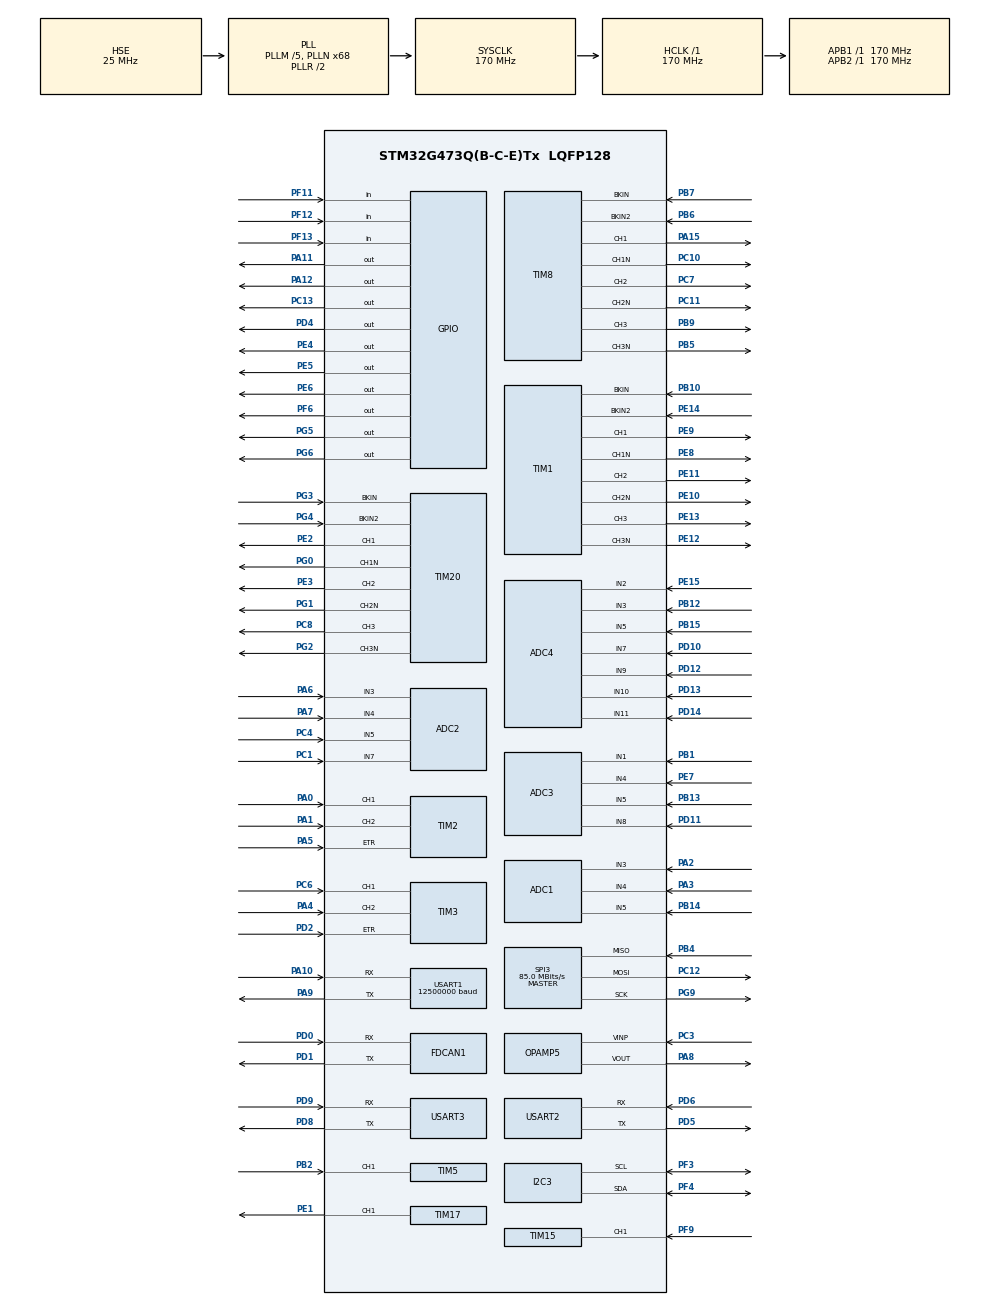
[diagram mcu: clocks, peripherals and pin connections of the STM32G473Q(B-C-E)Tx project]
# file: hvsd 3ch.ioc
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ADC1.Channel-0\#ChannelRegularConversion=ADC_CHANNEL_3
ADC1.ClockPrescaler=ADC_CLOCK_SYNC_PCLK_DIV4
ADC1.NbrOfConversionFlag=1
ADC1.OffsetNumber-0\#ChannelRegularConversion=ADC_OFFSET_NONE
ADC1.Rank-0\#ChannelRegularConversion=1
ADC1.SamplingTime-0\#ChannelRegularConversion=ADC_SAMPLETIME_2CYCLES_5
ADC1.master=1
ADC2.Channel-1\#ChannelRegularConversion=ADC_CHANNEL_3
ADC2.NbrOfConversionFlag=1
ADC2.OffsetNumber-1\#ChannelRegularConversion=ADC_OFFSET_NONE
ADC2.Rank-1\#ChannelRegularConversion=1
ADC2.SamplingTime-1\#ChannelRegularConversion=ADC_SAMPLETIME_2CYCLES_5
ADC3.Channel-1\#ChannelRegularConversion=ADC_CHANNEL_1
ADC3.NbrOfConversionFlag=1
ADC3.OffsetNumber-1\#ChannelRegularConversion=ADC_OFFSET_NONE
ADC3.Rank-1\#ChannelRegularConversion=1
ADC3.SamplingTime-1\#ChannelRegularConversion=ADC_SAMPLETIME_2CYCLES_5
ADC3.master=1
ADC4.Channel-0\#ChannelRegularConversion=ADC_CHANNEL_3
ADC4.NbrOfConversionFlag=1
ADC4.OffsetNumber-0\#ChannelRegularConversion=ADC_OFFSET_NONE
ADC4.Rank-0\#ChannelRegularConversion=1
ADC4.SamplingTime-0\#ChannelRegularConversion=ADC_SAMPLETIME_2CYCLES_5
FDCAN1.CalculateBaudRateNominal=3541666
FDCAN1.CalculateTimeBitNominal=282
FDCAN1.CalculateTimeQuantumNominal=94.11764705882354
I2C3.Timing=0x40B285C2
Mcu.Family=STM32G4
Mcu.Name=STM32G473Q(B-C-E)Tx
Mcu.Package=LQFP128
NVIC.PriorityGroup=NVIC_PRIORITYGROUP_4
OPAMP5.PowerMode=OPAMP_POWERMODE_NORMALSPEED
PA0.Signal=S_TIM2_CH1
PA1.Signal=S_TIM2_CH2
PA10.Mode=Asynchronous
PA10.Signal=USART1_RX
PA11.Signal=GPIO_Output
PA12.Signal=GPIO_Output
PA13.Signal=SYS_JTMS-SWDIO
PA14.Signal=SYS_JTCK-SWCLK
PA15.Signal=S_TIM8_CH1
PA2.Mode=IN3-Single-Ended
PA2.Signal=ADC1_IN3
PA3.Mode=IN4-Single-Ended
PA3.Signal=ADC1_IN4
PA4.Signal=S_TIM3_CH2
PA5.Signal=S_TIM2_ETR
PA6.Mode=IN3-Single-Ended
PA6.Signal=ADC2_IN3
PA7.Mode=IN4-Single-Ended
PA7.Signal=ADC2_IN4
PA8.Mode=Follower
PA8.Signal=OPAMP5_VOUT
PA9.Mode=Asynchronous
PA9.Signal=USART1_TX
PB0.Signal=OPAMP2_VINP
PB1.Mode=IN1-Single-Ended
PB1.Signal=ADC3_IN1
PB10.Mode=Activate-Break-Input
PB10.Signal=TIM1_BKIN
PB12.Mode=IN3-Single-Ended
PB12.Signal=ADC4_IN3
PB13.Mode=IN5-Single-Ended
PB13.Signal=ADC3_IN5
PB14.Mode=IN5-Single-Ended
PB14.Signal=ADC1_IN5
PB15.Mode=IN5-Single-Ended
PB15.Signal=ADC4_IN5
PB2.Signal=S_TIM5_CH1
PB3.Signal=SYS_JTDO-SWO
PB4.Mode=Full_Duplex_Master
PB4.Signal=SPI3_MISO
PB5.Mode=PWM Generation3 CH3 CH3N
PB5.Signal=TIM8_CH3N
PB6.Mode=Activate-Break-Input-2
PB6.Signal=TIM8_BKIN2
PB7.Mode=Activate-Break-Input
PB7.Signal=TIM8_BKIN
PB9.Signal=S_TIM8_CH3
PC1.Mode=IN7-Single-Ended
PC1.Signal=ADC2_IN7
PC10.Mode=PWM Generation1 CH1 CH1N
PC10.Signal=TIM8_CH1N
PC11.Mode=PWM Generation2 CH2 CH2N
PC11.Signal=TIM8_CH2N
PC12.Mode=Full_Duplex_Master
PC12.Signal=SPI3_MOSI
PC13.Signal=GPIO_Output
PC3.Mode=Follower
PC3.Signal=OPAMP5_VINP
PC4.Mode=IN5-Single-Ended
PC4.Signal=ADC2_IN5
PC6.Signal=S_TIM3_CH1
PC7.Signal=S_TIM8_CH2
PC8.Signal=S_TIM20_CH3
PD0.Mode=FDCAN_Activate
PD0.Signal=FDCAN1_RX
PD1.Mode=FDCAN_Activate
PD1.Signal=FDCAN1_TX
PD10.Mode=IN7-Single-Ended
PD10.Signal=ADC4_IN7
PD11.Mode=IN8-Single-Ended
PD11.Signal=ADC3_IN8
PD12.Mode=IN9-Single-Ended
PD12.Signal=ADC4_IN9
PD13.Mode=IN10-Single-Ended
PD13.Signal=ADC4_IN10
PD14.Mode=IN11-Single-Ended
PD14.Signal=ADC4_IN11
PD2.Signal=S_TIM3_ETR
PD4.Signal=GPIO_Output
PD5.Mode=Asynchronous
PD5.Signal=USART2_TX
PD6.Mode=Asynchronous
PD6.Signal=USART2_RX
PD8.Mode=Asynchronous
PD8.Signal=USART3_TX
PD9.Mode=Asynchronous
PD9.Signal=USART3_RX
PE0.Signal=S_TIM4_ETR
PE1.Signal=S_TIM17_CH1
PE10.Mode=PWM Generation2 CH2 CH2N
PE10.Signal=TIM1_CH2N
PE11.Signal=S_TIM1_CH2
PE12.Mode=PWM Generation3 CH3 CH3N
PE12.Signal=TIM1_CH3N
PE13.Signal=S_TIM1_CH3
PE14.Mode=Activate-Break-Input-2
PE14.Signal=TIM1_BKIN2
PE15.Mode=IN2-Single-Ended
PE15.Signal=ADC4_IN2
PE2.Signal=S_TIM20_CH1
PE3.Signal=S_TIM20_CH2
PE4.Signal=GPIO_Output
PE5.Signal=GPIO_Output
PE6.Signal=GPIO_Output
PE7.Mode=IN4-Single-Ended
PE7.Signal=ADC3_IN4
PE8.Mode=PWM Generation1 CH1 CH1N
PE8.Signal=TIM1_CH1N
PE9.Signal=S_TIM1_CH1
PF0-OSC_IN.Mode=HSE-External-Clock-Source
PF0-OSC_IN.Signal=RCC_OSC_IN
PF11.Signal=GPIO_Input
PF12.Signal=GPIO_Input
PF13.Signal=GPIO_Input
PF3.Mode=I2C
PF3.Signal=I2C3_SCL
PF4.Mode=I2C
PF4.Signal=I2C3_SDA
PF6.Signal=GPIO_Output
PF9.Signal=S_TIM15_CH1
PG0.Mode=PWM Generation1 CH1 CH1N
PG0.Signal=TIM20_CH1N
PG1.Mode=PWM Generation2 CH2 CH2N
PG1.Signal=TIM20_CH2N
PG2.Mode=PWM Generation3 CH3 CH3N
PG2.Signal=TIM20_CH3N
PG3.Mode=Activate-Break-Input
PG3.Signal=TIM20_BKIN
PG4.Mode=Activate-Break-Input-2
PG4.Signal=TIM20_BKIN2
PG5.Signal=GPIO_Output
PG6.Signal=GPIO_Output
PG9.Mode=Full_Duplex_Master
PG9.Signal=SPI3_SCK
ProjectManager.HeapSize=0x200
ProjectManager.StackSize=0x400
ProjectManager.TargetToolchain=STM32CubeIDE
RCC.ADC12Freq_Value=170000000
RCC.ADC345Freq_Value=170000000
RCC.AHBFreq_Value=170000000
RCC.APB1Freq_Value=170000000
RCC.APB1TimFreq_Value=170000000
RCC.APB2Freq_Value=170000000
RCC.APB2TimFreq_Value=170000000
RCC.CK48CLockSelection=RCC_USBCLKSOURCE_HSI48
RCC.CortexFreq_Value=170000000
RCC.EXTERNAL_CLOCK_VALUE=12288000
RCC.HCLKFreq_Value=170000000
RCC.HSE_VALUE=25000000
RCC.HSI48_VALUE=48000000
RCC.HSI_VALUE=16000000
RCC.LSE_VALUE=32768
RCC.PLLM=RCC_PLLM_DIV4
RCC.PLLN=85
RCC.PLLP=RCC_PLLP_DIV7
RCC.SYSCLKFreq_VALUE=170000000
RCC.SYSCLKSource=RCC_SYSCLKSOURCE_PLLCLK
RCC.USART2CLockSelection=RCC_USART2CLKSOURCE_SYSCLK
RCC.USART3CLockSelection=RCC_USART3CLKSOURCE_SYSCLK
RCC.USBFreq_Value=48000000
RCC.VCOOutputFreq_Value=340000000
SH.S_TIM15_CH1.0=TIM15_CH1,TriggerSource_TI1FP1
SH.S_TIM17_CH1.0=TIM17_CH1,PWM Generation1 CH1
SH.S_TIM1_CH1.0=TIM1_CH1,PWM Generation1 CH1 CH1N
SH.S_TIM1_CH2.0=TIM1_CH2,PWM Generation2 CH2 CH2N
SH.S_TIM1_CH3.0=TIM1_CH3,PWM Generation3 CH3 CH3N
SH.S_TIM20_CH1.0=TIM20_CH1,PWM Generation1 CH1 CH1N
SH.S_TIM20_CH2.0=TIM20_CH2,PWM Generation2 CH2 CH2N
SH.S_TIM20_CH3.0=TIM20_CH3,PWM Generation3 CH3 CH3N
SH.S_TIM2_CH1.0=TIM2_CH1,Encoder_Interface_w_index
SH.S_TIM2_CH2.0=TIM2_CH2,Encoder_Interface_w_index
SH.S_TIM2_ETR.0=TIM2_ETR,Encoder_Interface_w_index
SH.S_TIM3_CH1.0=TIM3_CH1,Encoder_Interface_w_index
SH.S_TIM3_CH2.0=TIM3_CH2,Encoder_Interface_w_index
SH.S_TIM3_ETR.0=TIM3_ETR,Encoder_Interface_w_index
SH.S_TIM4_ETR.0=TIM4_ETR
SH.S_TIM5_CH1.0=TIM5_CH1,Input_Capture1_from_TI1
SH.S_TIM8_CH1.0=TIM8_CH1,PWM Generation1 CH1 CH1N
SH.S_TIM8_CH2.0=TIM8_CH2,PWM Generation2 CH2 CH2N
SH.S_TIM8_CH3.0=TIM8_CH3,PWM Generation3 CH3 CH3N
SPI3.BaudRatePrescaler=SPI_BAUDRATEPRESCALER_2
SPI3.CalculateBaudRate=85.0 MBits/s
SPI3.Direction=SPI_DIRECTION_2LINES
SPI3.Mode=SPI_MODE_MASTER
SPI3.VirtualType=VM_MASTER
TIM1.Channel-PWM\ Generation1\ CH1\ CH1N=TIM_CHANNEL_1
TIM1.Channel-PWM\ Generation2\ CH2\ CH2N=TIM_CHANNEL_2
TIM1.Channel-PWM\ Generation3\ CH3\ CH3N=TIM_CHANNEL_3
TIM15.Slave_TriggerFilter=15
TIM17.AutoReloadPreload=TIM_AUTORELOAD_PRELOAD_ENABLE
TIM17.Channel=TIM_CHANNEL_1
TIM17.PeriodNoDither=1000
TIM17.Prescaler=3
TIM17.PulseNoDither_1=500
TIM20.Channel-PWM\ Generation1\ CH1\ CH1N=TIM_CHANNEL_1
TIM20.Channel-PWM\ Generation2\ CH2\ CH2N=TIM_CHANNEL_2
TIM20.Channel-PWM\ Generation3\ CH3\ CH3N=TIM_CHANNEL_3
TIM5.Channel-Input_Capture1_from_TI1=TIM_CHANNEL_1
TIM8.Channel-PWM\ Generation1\ CH1\ CH1N=TIM_CHANNEL_1
TIM8.Channel-PWM\ Generation2\ CH2\ CH2N=TIM_CHANNEL_2
TIM8.Channel-PWM\ Generation3\ CH3\ CH3N=TIM_CHANNEL_3
USART1.BaudRate=12500000
USART1.OverSampling=UART_OVERSAMPLING_8
USART1.SwapParam=ADVFEATURE_SWAP_DISABLE
USART1.VirtualMode-Asynchronous=VM_ASYNC
USART2.VirtualMode-Asynchronous=VM_ASYNC
USART3.VirtualMode-Asynchronous=VM_ASYNC
VP_CORDIC_VS_CORDIC.Mode=CORDIC_Activate
VP_CRC_VS_CRC.Mode=CRC_Activate
VP_FMAC_VS_FMAC.Mode=FMAC_Activate
VP_SYS_VS_DBSignals.Mode=DisableDeadBatterySignals
VP_TIM15_VS_ControllerModeClock.Mode=Clock Mode
VP_TIM17_VS_ClockSourceINT.Mode=Enable_Timer
VP_TIM1_VS_ClockSourceINT.Mode=Internal
VP_TIM20_VS_ClockSourceINT.Mode=Internal
VP_TIM8_VS_ClockSourceINT.Mode=Internal
board=custom

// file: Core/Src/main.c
/* USER CODE BEGIN Header */
/**
  ******************************************************************************
  * @file           : main.c
  * @brief          : Main program body
  ******************************************************************************
  * @attention
  *
  * Copyright (c) 2025 STMicroelectronics.
  * All rights reserved.
  *
  * This software is licensed under terms that can be found in the LICENSE file
  * in the root directory of this software component.
  * If no LICENSE file comes with this software, it is provided AS-IS.
  *
  ******************************************************************************
  */
/* USER CODE END Header */
#include "main.h"

ADC_HandleTypeDef hadc1;
ADC_HandleTypeDef hadc2;
ADC_HandleTypeDef hadc3;
ADC_HandleTypeDef hadc4;

CORDIC_HandleTypeDef hcordic;

CRC_HandleTypeDef hcrc;

FDCAN_HandleTypeDef hfdcan1;

FMAC_HandleTypeDef hfmac;

I2C_HandleTypeDef hi2c3;

OPAMP_HandleTypeDef hopamp5;

SPI_HandleTypeDef hspi3;

TIM_HandleTypeDef htim1;
TIM_HandleTypeDef htim2;
TIM_HandleTypeDef htim3;
TIM_HandleTypeDef htim5;
TIM_HandleTypeDef htim8;
TIM_HandleTypeDef htim15;
TIM_HandleTypeDef htim17;
TIM_HandleTypeDef htim20;

UART_HandleTypeDef huart1;
UART_HandleTypeDef huart2;
UART_HandleTypeDef huart3;

void SystemClock_Config(void);
static void MX_GPIO_Init(void);
static void MX_TIM1_Init(void);
static void MX_TIM8_Init(void);
static void MX_TIM20_Init(void);
static void MX_ADC1_Init(void);
static void MX_ADC2_Init(void);
static void MX_ADC3_Init(void);
static void MX_CORDIC_Init(void);
static void MX_CRC_Init(void);
static void MX_FMAC_Init(void);
static void MX_TIM2_Init(void);
static void MX_TIM3_Init(void);
static void MX_USART1_UART_Init(void);
static void MX_OPAMP5_Init(void);
static void MX_FDCAN1_Init(void);
static void MX_I2C3_Init(void);
static void MX_SPI3_Init(void);
static void MX_TIM5_Init(void);
static void MX_TIM15_Init(void);
static void MX_TIM17_Init(void);
static void MX_USART2_UART_Init(void);
static void MX_USART3_UART_Init(void);
static void MX_ADC4_Init(void);

int main(void)
{

  /* MCU Configuration--------------------------------------------------------*/

  /* Reset of all peripherals, Initializes the Flash interface and the Systick. */
  HAL_Init();

  /* Configure the system clock */
  SystemClock_Config();

  /* Initialize all configured peripherals */
  MX_GPIO_Init();
  MX_TIM1_Init();
  MX_TIM8_Init();
  MX_TIM20_Init();
  MX_ADC1_Init();
  MX_ADC2_Init();
  MX_ADC3_Init();
  MX_CORDIC_Init();
  MX_CRC_Init();
  MX_FMAC_Init();
  MX_TIM2_Init();
  MX_TIM3_Init();
  MX_USART1_UART_Init();
  MX_OPAMP5_Init();
  MX_FDCAN1_Init();
  MX_I2C3_Init();
  MX_SPI3_Init();
  MX_TIM5_Init();
  MX_TIM15_Init();
  MX_TIM17_Init();
  MX_USART2_UART_Init();
  MX_USART3_UART_Init();
  MX_ADC4_Init();
  /* USER CODE BEGIN 2 */

  HAL_TIM_PWM_Start(&htim17, TIM_CHANNEL_1);

  /* USER CODE END 2 */

  /* Infinite loop */
  /* USER CODE BEGIN WHILE */
  while (1)
  {

	for(uint16_t val = 0; val < 999; val++){
		TIM17->CCR1 = val;
		HAL_Delay(20);
	}

	for(uint16_t val = 999; val > 0; val--){
		TIM17->CCR1 = val;
		HAL_Delay(20);
	}

//	// port 1 led 0
//	HAL_GPIO_WritePin(GPIOE, GPIO_PIN_6, GPIO_PIN_SET);
//	HAL_Delay(500);
//
//	HAL_GPIO_WritePin(GPIOE, GPIO_PIN_6, GPIO_PIN_RESET);
//	HAL_Delay(500);
//
//	// port 1 led 1
//	HAL_GPIO_WritePin(GPIOE, GPIO_PIN_5, GPIO_PIN_SET);
//	HAL_Delay(500);
//
//	HAL_GPIO_WritePin(GPIOE, GPIO_PIN_5, GPIO_PIN_RESET);
//	HAL_Delay(500);
//
//	// port 2 led 0
//	HAL_GPIO_WritePin(GPIOC, GPIO_PIN_13, GPIO_PIN_SET);
//	HAL_Delay(500);
//
//	HAL_GPIO_WritePin(GPIOC, GPIO_PIN_13, GPIO_PIN_RESET);
//	HAL_Delay(500);
//
//	// port 2 led 1
//	HAL_GPIO_WritePin(GPIOE, GPIO_PIN_4, GPIO_PIN_SET);
//	HAL_Delay(500);
//
//	HAL_GPIO_WritePin(GPIOE, GPIO_PIN_4, GPIO_PIN_RESET);
//	HAL_Delay(500);
//
//	// port 1 led 1
//	HAL_GPIO_WritePin(GPIOA, GPIO_PIN_11, GPIO_PIN_SET);
//	HAL_Delay(500);
//
//	HAL_GPIO_WritePin(GPIOA, GPIO_PIN_11, GPIO_PIN_RESET);
//	HAL_Delay(500);
//
//	// port 1 led 1
//	HAL_GPIO_WritePin(GPIOA, GPIO_PIN_12, GPIO_PIN_SET);
//	HAL_Delay(500);
//
//	HAL_GPIO_WritePin(GPIOA, GPIO_PIN_12, GPIO_PIN_RESET);
//	HAL_Delay(500);

    /* USER CODE END WHILE */

  }
}

void SystemClock_Config(void)
{
  RCC_OscInitTypeDef RCC_OscInitStruct = {0};
  RCC_ClkInitTypeDef RCC_ClkInitStruct = {0};

  /** Configure the main internal regulator output voltage
  */
  HAL_PWREx_ControlVoltageScaling(PWR_REGULATOR_VOLTAGE_SCALE1_BOOST);

  /** Initializes the RCC Oscillators according to the specified parameters
  * in the RCC_OscInitTypeDef structure.
  */
  RCC_OscInitStruct.OscillatorType = RCC_OSCILLATORTYPE_HSE;
  RCC_OscInitStruct.HSEState = RCC_HSE_BYPASS;
  RCC_OscInitStruct.PLL.PLLState = RCC_PLL_ON;
  RCC_OscInitStruct.PLL.PLLSource = RCC_PLLSOURCE_HSE;
  RCC_OscInitStruct.PLL.PLLM = RCC_PLLM_DIV5;
  RCC_OscInitStruct.PLL.PLLN = 68;
  RCC_OscInitStruct.PLL.PLLP = RCC_PLLP_DIV2;
  RCC_OscInitStruct.PLL.PLLQ = RCC_PLLQ_DIV2;
  RCC_OscInitStruct.PLL.PLLR = RCC_PLLR_DIV2;
  if (HAL_RCC_OscConfig(&RCC_OscInitStruct) != HAL_OK)
  {
    Error_Handler();
  }

  /** Initializes the CPU, AHB and APB buses clocks
  */
  RCC_ClkInitStruct.ClockType = RCC_CLOCKTYPE_HCLK|RCC_CLOCKTYPE_SYSCLK
                              |RCC_CLOCKTYPE_PCLK1|RCC_CLOCKTYPE_PCLK2;
  RCC_ClkInitStruct.SYSCLKSource = RCC_SYSCLKSOURCE_PLLCLK;
  RCC_ClkInitStruct.AHBCLKDivider = RCC_SYSCLK_DIV1;
  RCC_ClkInitStruct.APB1CLKDivider = RCC_HCLK_DIV1;
  RCC_ClkInitStruct.APB2CLKDivider = RCC_HCLK_DIV1;

  if (HAL_RCC_ClockConfig(&RCC_ClkInitStruct, FLASH_LATENCY_4) != HAL_OK)
  {
    Error_Handler();
  }
}

static void MX_ADC1_Init(void)
{

  ADC_MultiModeTypeDef multimode = {0};
  ADC_ChannelConfTypeDef sConfig = {0};

  /** Common config
  */
  hadc1.Instance = ADC1;
  hadc1.Init.ClockPrescaler = ADC_CLOCK_SYNC_PCLK_DIV4;
  hadc1.Init.Resolution = ADC_RESOLUTION_12B;
  hadc1.Init.DataAlign = ADC_DATAALIGN_RIGHT;
  hadc1.Init.GainCompensation = 0;
  hadc1.Init.ScanConvMode = ADC_SCAN_DISABLE;
  hadc1.Init.EOCSelection = ADC_EOC_SINGLE_CONV;
  hadc1.Init.LowPowerAutoWait = DISABLE;
  hadc1.Init.ContinuousConvMode = DISABLE;
  hadc1.Init.NbrOfConversion = 1;
  hadc1.Init.DiscontinuousConvMode = DISABLE;
  hadc1.Init.ExternalTrigConv = ADC_SOFTWARE_START;
  hadc1.Init.ExternalTrigConvEdge = ADC_EXTERNALTRIGCONVEDGE_NONE;
  hadc1.Init.DMAContinuousRequests = DISABLE;
  hadc1.Init.Overrun = ADC_OVR_DATA_PRESERVED;
  hadc1.Init.OversamplingMode = DISABLE;
  if (HAL_ADC_Init(&hadc1) != HAL_OK)
  {
    Error_Handler();
  }

  /** Configure the ADC multi-mode
  */
  multimode.Mode = ADC_MODE_INDEPENDENT;
  if (HAL_ADCEx_MultiModeConfigChannel(&hadc1, &multimode) != HAL_OK)
  {
    Error_Handler();
  }

  /** Configure Regular Channel
  */
  sConfig.Channel = ADC_CHANNEL_3;
  sConfig.Rank = ADC_REGULAR_RANK_1;
  sConfig.SamplingTime = ADC_SAMPLETIME_2CYCLES_5;
  sConfig.SingleDiff = ADC_SINGLE_ENDED;
  sConfig.OffsetNumber = ADC_OFFSET_NONE;
  sConfig.Offset = 0;
  if (HAL_ADC_ConfigChannel(&hadc1, &sConfig) != HAL_OK)
  {
    Error_Handler();
  }

}

static void MX_ADC2_Init(void)
{

  ADC_ChannelConfTypeDef sConfig = {0};

  /** Common config
  */
  hadc2.Instance = ADC2;
  hadc2.Init.ClockPrescaler = ADC_CLOCK_SYNC_PCLK_DIV4;
  hadc2.Init.Resolution = ADC_RESOLUTION_12B;
  hadc2.Init.DataAlign = ADC_DATAALIGN_RIGHT;
  hadc2.Init.GainCompensation = 0;
  hadc2.Init.ScanConvMode = ADC_SCAN_DISABLE;
  hadc2.Init.EOCSelection = ADC_EOC_SINGLE_CONV;
  hadc2.Init.LowPowerAutoWait = DISABLE;
  hadc2.Init.ContinuousConvMode = DISABLE;
  hadc2.Init.NbrOfConversion = 1;
  hadc2.Init.DiscontinuousConvMode = DISABLE;
  hadc2.Init.ExternalTrigConv = ADC_SOFTWARE_START;
  hadc2.Init.ExternalTrigConvEdge = ADC_EXTERNALTRIGCONVEDGE_NONE;
  hadc2.Init.DMAContinuousRequests = DISABLE;
  hadc2.Init.Overrun = ADC_OVR_DATA_PRESERVED;
  hadc2.Init.OversamplingMode = DISABLE;
  if (HAL_ADC_Init(&hadc2) != HAL_OK)
  {
    Error_Handler();
  }

  /** Configure Regular Channel
  */
  sConfig.Channel = ADC_CHANNEL_3;
  sConfig.Rank = ADC_REGULAR_RANK_1;
  sConfig.SamplingTime = ADC_SAMPLETIME_2CYCLES_5;
  sConfig.SingleDiff = ADC_SINGLE_ENDED;
  sConfig.OffsetNumber = ADC_OFFSET_NONE;
  sConfig.Offset = 0;
  if (HAL_ADC_ConfigChannel(&hadc2, &sConfig) != HAL_OK)
  {
    Error_Handler();
  }

}

static void MX_ADC3_Init(void)
{

  ADC_MultiModeTypeDef multimode = {0};
  ADC_ChannelConfTypeDef sConfig = {0};

  /** Common config
  */
  hadc3.Instance = ADC3;
  hadc3.Init.ClockPrescaler = ADC_CLOCK_SYNC_PCLK_DIV4;
  hadc3.Init.Resolution = ADC_RESOLUTION_12B;
  hadc3.Init.DataAlign = ADC_DATAALIGN_RIGHT;
  hadc3.Init.GainCompensation = 0;
  hadc3.Init.ScanConvMode = ADC_SCAN_DISABLE;
  hadc3.Init.EOCSelection = ADC_EOC_SINGLE_CONV;
  hadc3.Init.LowPowerAutoWait = DISABLE;
  hadc3.Init.ContinuousConvMode = DISABLE;
  hadc3.Init.NbrOfConversion = 1;
  hadc3.Init.DiscontinuousConvMode = DISABLE;
  hadc3.Init.ExternalTrigConv = ADC_SOFTWARE_START;
  hadc3.Init.ExternalTrigConvEdge = ADC_EXTERNALTRIGCONVEDGE_NONE;
  hadc3.Init.DMAContinuousRequests = DISABLE;
  hadc3.Init.Overrun = ADC_OVR_DATA_PRESERVED;
  hadc3.Init.OversamplingMode = DISABLE;
  if (HAL_ADC_Init(&hadc3) != HAL_OK)
  {
    Error_Handler();
  }

  /** Configure the ADC multi-mode
  */
  multimode.Mode = ADC_MODE_INDEPENDENT;
  if (HAL_ADCEx_MultiModeConfigChannel(&hadc3, &multimode) != HAL_OK)
  {
    Error_Handler();
  }

  /** Configure Regular Channel
  */
  sConfig.Channel = ADC_CHANNEL_1;
  sConfig.Rank = ADC_REGULAR_RANK_1;
  sConfig.SamplingTime = ADC_SAMPLETIME_2CYCLES_5;
  sConfig.SingleDiff = ADC_SINGLE_ENDED;
  sConfig.OffsetNumber = ADC_OFFSET_NONE;
  sConfig.Offset = 0;
  if (HAL_ADC_ConfigChannel(&hadc3, &sConfig) != HAL_OK)
  {
    Error_Handler();
  }

}

static void MX_ADC4_Init(void)
{

  ADC_ChannelConfTypeDef sConfig = {0};

  /** Common config
  */
  hadc4.Instance = ADC4;
  hadc4.Init.ClockPrescaler = ADC_CLOCK_SYNC_PCLK_DIV4;
  hadc4.Init.Resolution = ADC_RESOLUTION_12B;
  hadc4.Init.DataAlign = ADC_DATAALIGN_RIGHT;
  hadc4.Init.GainCompensation = 0;
  hadc4.Init.ScanConvMode = ADC_SCAN_DISABLE;
  hadc4.Init.EOCSelection = ADC_EOC_SINGLE_CONV;
  hadc4.Init.LowPowerAutoWait = DISABLE;
  hadc4.Init.ContinuousConvMode = DISABLE;
  hadc4.Init.NbrOfConversion = 1;
  hadc4.Init.DiscontinuousConvMode = DISABLE;
  hadc4.Init.ExternalTrigConv = ADC_SOFTWARE_START;
  hadc4.Init.ExternalTrigConvEdge = ADC_EXTERNALTRIGCONVEDGE_NONE;
  hadc4.Init.DMAContinuousRequests = DISABLE;
  hadc4.Init.Overrun = ADC_OVR_DATA_PRESERVED;
  hadc4.Init.OversamplingMode = DISABLE;
  if (HAL_ADC_Init(&hadc4) != HAL_OK)
  {
    Error_Handler();
  }

  /** Configure Regular Channel
  */
  sConfig.Channel = ADC_CHANNEL_3;
  sConfig.Rank = ADC_REGULAR_RANK_1;
  sConfig.SamplingTime = ADC_SAMPLETIME_2CYCLES_5;
  sConfig.SingleDiff = ADC_SINGLE_ENDED;
  sConfig.OffsetNumber = ADC_OFFSET_NONE;
  sConfig.Offset = 0;
  if (HAL_ADC_ConfigChannel(&hadc4, &sConfig) != HAL_OK)
  {
    Error_Handler();
  }

}

static void MX_CORDIC_Init(void)
{

  hcordic.Instance = CORDIC;
  if (HAL_CORDIC_Init(&hcordic) != HAL_OK)
  {
    Error_Handler();
  }

}

static void MX_CRC_Init(void)
{

  hcrc.Instance = CRC;
  hcrc.Init.DefaultPolynomialUse = DEFAULT_POLYNOMIAL_ENABLE;
  hcrc.Init.DefaultInitValueUse = DEFAULT_INIT_VALUE_ENABLE;
  hcrc.Init.InputDataInversionMode = CRC_INPUTDATA_INVERSION_NONE;
  hcrc.Init.OutputDataInversionMode = CRC_OUTPUTDATA_INVERSION_DISABLE;
  hcrc.InputDataFormat = CRC_INPUTDATA_FORMAT_BYTES;
  if (HAL_CRC_Init(&hcrc) != HAL_OK)
  {
    Error_Handler();
  }

}

static void MX_FDCAN1_Init(void)
{

  hfdcan1.Instance = FDCAN1;
  hfdcan1.Init.ClockDivider = FDCAN_CLOCK_DIV1;
  hfdcan1.Init.FrameFormat = FDCAN_FRAME_CLASSIC;
  hfdcan1.Init.Mode = FDCAN_MODE_NORMAL;
  hfdcan1.Init.AutoRetransmission = DISABLE;
  hfdcan1.Init.TransmitPause = DISABLE;
  hfdcan1.Init.ProtocolException = DISABLE;
  hfdcan1.Init.NominalPrescaler = 16;
  hfdcan1.Init.NominalSyncJumpWidth = 1;
  hfdcan1.Init.NominalTimeSeg1 = 1;
  hfdcan1.Init.NominalTimeSeg2 = 1;
  hfdcan1.Init.DataPrescaler = 1;
  hfdcan1.Init.DataSyncJumpWidth = 1;
  hfdcan1.Init.DataTimeSeg1 = 1;
  hfdcan1.Init.DataTimeSeg2 = 1;
  hfdcan1.Init.StdFiltersNbr = 0;
  hfdcan1.Init.ExtFiltersNbr = 0;
  hfdcan1.Init.TxFifoQueueMode = FDCAN_TX_FIFO_OPERATION;
  if (HAL_FDCAN_Init(&hfdcan1) != HAL_OK)
  {
    Error_Handler();
  }

}

static void MX_FMAC_Init(void)
{

  hfmac.Instance = FMAC;
  if (HAL_FMAC_Init(&hfmac) != HAL_OK)
  {
    Error_Handler();
  }

}

static void MX_I2C3_Init(void)
{

  hi2c3.Instance = I2C3;
  hi2c3.Init.Timing = 0x40B285C2;
  hi2c3.Init.OwnAddress1 = 0;
  hi2c3.Init.AddressingMode = I2C_ADDRESSINGMODE_7BIT;
  hi2c3.Init.DualAddressMode = I2C_DUALADDRESS_DISABLE;
  hi2c3.Init.OwnAddress2 = 0;
  hi2c3.Init.OwnAddress2Masks = I2C_OA2_NOMASK;
  hi2c3.Init.GeneralCallMode = I2C_GENERALCALL_DISABLE;
  hi2c3.Init.NoStretchMode = I2C_NOSTRETCH_DISABLE;
  if (HAL_I2C_Init(&hi2c3) != HAL_OK)
  {
    Error_Handler();
  }

  /** Configure Analogue filter
  */
  if (HAL_I2CEx_ConfigAnalogFilter(&hi2c3, I2C_ANALOGFILTER_ENABLE) != HAL_OK)
  {
    Error_Handler();
  }

  /** Configure Digital filter
  */
  if (HAL_I2CEx_ConfigDigitalFilter(&hi2c3, 0) != HAL_OK)
  {
    Error_Handler();
  }

}

static void MX_OPAMP5_Init(void)
{

  hopamp5.Instance = OPAMP5;
  hopamp5.Init.PowerMode = OPAMP_POWERMODE_NORMALSPEED;
  hopamp5.Init.Mode = OPAMP_FOLLOWER_MODE;
  hopamp5.Init.NonInvertingInput = OPAMP_NONINVERTINGINPUT_IO2;
  hopamp5.Init.InternalOutput = DISABLE;
  hopamp5.Init.TimerControlledMuxmode = OPAMP_TIMERCONTROLLEDMUXMODE_DISABLE;
  hopamp5.Init.UserTrimming = OPAMP_TRIMMING_FACTORY;
  if (HAL_OPAMP_Init(&hopamp5) != HAL_OK)
  {
    Error_Handler();
  }

}

static void MX_SPI3_Init(void)
{

  /* SPI3 parameter configuration*/
  hspi3.Instance = SPI3;
  hspi3.Init.Mode = SPI_MODE_MASTER;
  hspi3.Init.Direction = SPI_DIRECTION_2LINES;
  hspi3.Init.DataSize = SPI_DATASIZE_4BIT;
  hspi3.Init.CLKPolarity = SPI_POLARITY_LOW;
  hspi3.Init.CLKPhase = SPI_PHASE_1EDGE;
  hspi3.Init.NSS = SPI_NSS_SOFT;
  hspi3.Init.BaudRatePrescaler = SPI_BAUDRATEPRESCALER_2;
  hspi3.Init.FirstBit = SPI_FIRSTBIT_MSB;
  hspi3.Init.TIMode = SPI_TIMODE_DISABLE;
  hspi3.Init.CRCCalculation = SPI_CRCCALCULATION_DISABLE;
  hspi3.Init.CRCPolynomial = 7;
  hspi3.Init.CRCLength = SPI_CRC_LENGTH_DATASIZE;
  hspi3.Init.NSSPMode = SPI_NSS_PULSE_ENABLE;
  if (HAL_SPI_Init(&hspi3) != HAL_OK)
  {
    Error_Handler();
  }

}

static void MX_TIM1_Init(void)
{

  TIM_ClockConfigTypeDef sClockSourceConfig = {0};
  TIM_MasterConfigTypeDef sMasterConfig = {0};
  TIMEx_BreakInputConfigTypeDef sBreakInputConfig = {0};
  TIM_OC_InitTypeDef sConfigOC = {0};
  TIM_BreakDeadTimeConfigTypeDef sBreakDeadTimeConfig = {0};

  htim1.Instance = TIM1;
  htim1.Init.Prescaler = 0;
  htim1.Init.CounterMode = TIM_COUNTERMODE_UP;
  htim1.Init.Period = 65535;
  htim1.Init.ClockDivision = TIM_CLOCKDIVISION_DIV1;
  htim1.Init.RepetitionCounter = 0;
  htim1.Init.AutoReloadPreload = TIM_AUTORELOAD_PRELOAD_DISABLE;
  if (HAL_TIM_Base_Init(&htim1) != HAL_OK)
  {
    Error_Handler();
  }
  sClockSourceConfig.ClockSource = TIM_CLOCKSOURCE_INTERNAL;
  if (HAL_TIM_ConfigClockSource(&htim1, &sClockSourceConfig) != HAL_OK)
  {
    Error_Handler();
  }
  if (HAL_TIM_PWM_Init(&htim1) != HAL_OK)
  {
    Error_Handler();
  }
  sMasterConfig.MasterOutputTrigger = TIM_TRGO_RESET;
  sMasterConfig.MasterOutputTrigger2 = TIM_TRGO2_RESET;
  sMasterConfig.MasterSlaveMode = TIM_MASTERSLAVEMODE_DISABLE;
  if (HAL_TIMEx_MasterConfigSynchronization(&htim1, &sMasterConfig) != HAL_OK)
  {
    Error_Handler();
  }
  sBreakInputConfig.Source = TIM_BREAKINPUTSOURCE_BKIN;
  sBreakInputConfig.Enable = TIM_BREAKINPUTSOURCE_ENABLE;
  sBreakInputConfig.Polarity = TIM_BREAKINPUTSOURCE_POLARITY_HIGH;
  if (HAL_TIMEx_ConfigBreakInput(&htim1, TIM_BREAKINPUT_BRK, &sBreakInputConfig) != HAL_OK)
  {
    Error_Handler();
  }
  if (HAL_TIMEx_ConfigBreakInput(&htim1, TIM_BREAKINPUT_BRK2, &sBreakInputConfig) != HAL_OK)
  {
    Error_Handler();
  }
  sConfigOC.OCMode = TIM_OCMODE_PWM1;
  sConfigOC.Pulse = 0;
  sConfigOC.OCPolarity = TIM_OCPOLARITY_HIGH;
  sConfigOC.OCNPolarity = TIM_OCNPOLARITY_HIGH;
  sConfigOC.OCFastMode = TIM_OCFAST_DISABLE;
  sConfigOC.OCIdleState = TIM_OCIDLESTATE_RESET;
  sConfigOC.OCNIdleState = TIM_OCNIDLESTATE_RESET;
  if (HAL_TIM_PWM_ConfigChannel(&htim1, &sConfigOC, TIM_CHANNEL_1) != HAL_OK)
  {
    Error_Handler();
  }
  if (HAL_TIM_PWM_ConfigChannel(&htim1, &sConfigOC, TIM_CHANNEL_2) != HAL_OK)
  {
    Error_Handler();
  }
  if (HAL_TIM_PWM_ConfigChannel(&htim1, &sConfigOC, TIM_CHANNEL_3) != HAL_OK)
  {
    Error_Handler();
  }
  sBreakDeadTimeConfig.OffStateRunMode = TIM_OSSR_ENABLE;
  sBreakDeadTimeConfig.OffStateIDLEMode = TIM_OSSI_ENABLE;
  sBreakDeadTimeConfig.LockLevel = TIM_LOCKLEVEL_OFF;
  sBreakDeadTimeConfig.DeadTime = 0;
  sBreakDeadTimeConfig.BreakState = TIM_BREAK_ENABLE;
  sBreakDeadTimeConfig.BreakPolarity = TIM_BREAKPOLARITY_HIGH;
  sBreakDeadTimeConfig.BreakFilter = 0;
  sBreakDeadTimeConfig.BreakAFMode = TIM_BREAK_AFMODE_INPUT;
  sBreakDeadTimeConfig.Break2State = TIM_BREAK2_ENABLE;
  sBreakDeadTimeConfig.Break2Polarity = TIM_BREAK2POLARITY_HIGH;
  sBreakDeadTimeConfig.Break2Filter = 0;
  sBreakDeadTimeConfig.Break2AFMode = TIM_BREAK_AFMODE_INPUT;
  sBreakDeadTimeConfig.AutomaticOutput = TIM_AUTOMATICOUTPUT_DISABLE;
  if (HAL_TIMEx_ConfigBreakDeadTime(&htim1, &sBreakDeadTimeConfig) != HAL_OK)
  {
    Error_Handler();
  }
  HAL_TIM_MspPostInit(&htim1);

}

static void MX_TIM2_Init(void)
{

  TIM_Encoder_InitTypeDef sConfig = {0};
  TIM_MasterConfigTypeDef sMasterConfig = {0};
  TIMEx_EncoderIndexConfigTypeDef sEncoderIndexConfig = {0};

  htim2.Instance = TIM2;
  htim2.Init.Prescaler = 0;
  htim2.Init.CounterMode = TIM_COUNTERMODE_UP;
  htim2.Init.Period = 4294967295;
  htim2.Init.ClockDivision = TIM_CLOCKDIVISION_DIV1;
  htim2.Init.AutoReloadPreload = TIM_AUTORELOAD_PRELOAD_DISABLE;
  sConfig.EncoderMode = TIM_ENCODERMODE_TI1;
  sConfig.IC1Polarity = TIM_ICPOLARITY_RISING;
  sConfig.IC1Selection = TIM_ICSELECTION_DIRECTTI;
  sConfig.IC1Prescaler = TIM_ICPSC_DIV1;
  sConfig.IC1Filter = 0;
  sConfig.IC2Polarity = TIM_ICPOLARITY_RISING;
  sConfig.IC2Selection = TIM_ICSELECTION_DIRECTTI;
  sConfig.IC2Prescaler = TIM_ICPSC_DIV1;
  sConfig.IC2Filter = 0;
  if (HAL_TIM_Encoder_Init(&htim2, &sConfig) != HAL_OK)
  {
    Error_Handler();
  }
  sMasterConfig.MasterOutputTrigger = TIM_TRGO_RESET;
  sMasterConfig.MasterSlaveMode = TIM_MASTERSLAVEMODE_DISABLE;
  if (HAL_TIMEx_MasterConfigSynchronization(&htim2, &sMasterConfig) != HAL_OK)
  {
    Error_Handler();
  }
  sEncoderIndexConfig.Polarity = TIM_ENCODERINDEX_POLARITY_NONINVERTED;
  sEncoderIndexConfig.Prescaler = TIM_ENCODERINDEX_PRESCALER_DIV1;
  sEncoderIndexConfig.Filter = 0;
  sEncoderIndexConfig.FirstIndexEnable = DISABLE;
  sEncoderIndexConfig.Position = TIM_ENCODERINDEX_POSITION_00;
  sEncoderIndexConfig.Direction = TIM_ENCODERINDEX_DIRECTION_UP_DOWN;
  if (HAL_TIMEx_ConfigEncoderIndex(&htim2, &sEncoderIndexConfig) != HAL_OK)
  {
    Error_Handler();
  }

}

static void MX_TIM3_Init(void)
{

  TIM_Encoder_InitTypeDef sConfig = {0};
  TIM_MasterConfigTypeDef sMasterConfig = {0};
  TIMEx_EncoderIndexConfigTypeDef sEncoderIndexConfig = {0};

  htim3.Instance = TIM3;
  htim3.Init.Prescaler = 0;
  htim3.Init.CounterMode = TIM_COUNTERMODE_UP;
  htim3.Init.Period = 65535;
  htim3.Init.ClockDivision = TIM_CLOCKDIVISION_DIV1;
  htim3.Init.AutoReloadPreload = TIM_AUTORELOAD_PRELOAD_DISABLE;
  sConfig.EncoderMode = TIM_ENCODERMODE_TI1;
  sConfig.IC1Polarity = TIM_ICPOLARITY_RISING;
  sConfig.IC1Selection = TIM_ICSELECTION_DIRECTTI;
  sConfig.IC1Prescaler = TIM_ICPSC_DIV1;
  sConfig.IC1Filter = 0;
  sConfig.IC2Polarity = TIM_ICPOLARITY_RISING;
  sConfig.IC2Selection = TIM_ICSELECTION_DIRECTTI;
  sConfig.IC2Prescaler = TIM_ICPSC_DIV1;
  sConfig.IC2Filter = 0;
  if (HAL_TIM_Encoder_Init(&htim3, &sConfig) != HAL_OK)
  {
    Error_Handler();
  }
  sMasterConfig.MasterOutputTrigger = TIM_TRGO_RESET;
  sMasterConfig.MasterSlaveMode = TIM_MASTERSLAVEMODE_DISABLE;
  if (HAL_TIMEx_MasterConfigSynchronization(&htim3, &sMasterConfig) != HAL_OK)
  {
    Error_Handler();
  }
  sEncoderIndexConfig.Polarity = TIM_ENCODERINDEX_POLARITY_NONINVERTED;
  sEncoderIndexConfig.Prescaler = TIM_ENCODERINDEX_PRESCALER_DIV1;
  sEncoderIndexConfig.Filter = 0;
  sEncoderIndexConfig.FirstIndexEnable = DISABLE;
  sEncoderIndexConfig.Position = TIM_ENCODERINDEX_POSITION_00;
  sEncoderIndexConfig.Direction = TIM_ENCODERINDEX_DIRECTION_UP_DOWN;
  if (HAL_TIMEx_ConfigEncoderIndex(&htim3, &sEncoderIndexConfig) != HAL_OK)
  {
    Error_Handler();
  }

}

static void MX_TIM5_Init(void)
{

  TIM_MasterConfigTypeDef sMasterConfig = {0};
  TIM_IC_InitTypeDef sConfigIC = {0};

  htim5.Instance = TIM5;
  htim5.Init.Prescaler = 0;
  htim5.Init.CounterMode = TIM_COUNTERMODE_UP;
  htim5.Init.Period = 4294967295;
  htim5.Init.ClockDivision = TIM_CLOCKDIVISION_DIV1;
  htim5.Init.AutoReloadPreload = TIM_AUTORELOAD_PRELOAD_DISABLE;
  if (HAL_TIM_IC_Init(&htim5) != HAL_OK)
  {
    Error_Handler();
  }
  sMasterConfig.MasterOutputTrigger = TIM_TRGO_RESET;
  sMasterConfig.MasterSlaveMode = TIM_MASTERSLAVEMODE_DISABLE;
  if (HAL_TIMEx_MasterConfigSynchronization(&htim5, &sMasterConfig) != HAL_OK)
  {
    Error_Handler();
  }
  sConfigIC.ICPolarity = TIM_INPUTCHANNELPOLARITY_RISING;
  sConfigIC.ICSelection = TIM_ICSELECTION_DIRECTTI;
  sConfigIC.ICPrescaler = TIM_ICPSC_DIV1;
  sConfigIC.ICFilter = 0;
  if (HAL_TIM_IC_ConfigChannel(&htim5, &sConfigIC, TIM_CHANNEL_1) != HAL_OK)
  {
    Error_Handler();
  }

}

static void MX_TIM8_Init(void)
{

  TIM_ClockConfigTypeDef sClockSourceConfig = {0};
  TIM_MasterConfigTypeDef sMasterConfig = {0};
  TIMEx_BreakInputConfigTypeDef sBreakInputConfig = {0};
  TIM_OC_InitTypeDef sConfigOC = {0};
  TIM_BreakDeadTimeConfigTypeDef sBreakDeadTimeConfig = {0};

  htim8.Instance = TIM8;
  htim8.Init.Prescaler = 0;
  htim8.Init.CounterMode = TIM_COUNTERMODE_UP;
  htim8.Init.Period = 65535;
  htim8.Init.ClockDivision = TIM_CLOCKDIVISION_DIV1;
  htim8.Init.RepetitionCounter = 0;
  htim8.Init.AutoReloadPreload = TIM_AUTORELOAD_PRELOAD_DISABLE;
  if (HAL_TIM_Base_Init(&htim8) != HAL_OK)
  {
    Error_Handler();
  }
  sClockSourceConfig.ClockSource = TIM_CLOCKSOURCE_INTERNAL;
  if (HAL_TIM_ConfigClockSource(&htim8, &sClockSourceConfig) != HAL_OK)
  {
    Error_Handler();
  }
  if (HAL_TIM_PWM_Init(&htim8) != HAL_OK)
  {
    Error_Handler();
  }
  sMasterConfig.MasterOutputTrigger = TIM_TRGO_RESET;
  sMasterConfig.MasterOutputTrigger2 = TIM_TRGO2_RESET;
  sMasterConfig.MasterSlaveMode = TIM_MASTERSLAVEMODE_DISABLE;
  if (HAL_TIMEx_MasterConfigSynchronization(&htim8, &sMasterConfig) != HAL_OK)
  {
    Error_Handler();
  }
  sBreakInputConfig.Source = TIM_BREAKINPUTSOURCE_BKIN;
  sBreakInputConfig.Enable = TIM_BREAKINPUTSOURCE_ENABLE;
  sBreakInputConfig.Polarity = TIM_BREAKINPUTSOURCE_POLARITY_HIGH;
  if (HAL_TIMEx_ConfigBreakInput(&htim8, TIM_BREAKINPUT_BRK, &sBreakInputConfig) != HAL_OK)
  {
    Error_Handler();
  }
  if (HAL_TIMEx_ConfigBreakInput(&htim8, TIM_BREAKINPUT_BRK2, &sBreakInputConfig) != HAL_OK)
  {
    Error_Handler();
  }
  sConfigOC.OCMode = TIM_OCMODE_PWM1;
  sConfigOC.Pulse = 0;
  sConfigOC.OCPolarity = TIM_OCPOLARITY_HIGH;
  sConfigOC.OCNPolarity = TIM_OCNPOLARITY_HIGH;
  sConfigOC.OCFastMode = TIM_OCFAST_DISABLE;
  sConfigOC.OCIdleState = TIM_OCIDLESTATE_RESET;
  sConfigOC.OCNIdleState = TIM_OCNIDLESTATE_RESET;
  if (HAL_TIM_PWM_ConfigChannel(&htim8, &sConfigOC, TIM_CHANNEL_1) != HAL_OK)
  {
    Error_Handler();
  }
  if (HAL_TIM_PWM_ConfigChannel(&htim8, &sConfigOC, TIM_CHANNEL_2) != HAL_OK)
  {
    Error_Handler();
  }
  if (HAL_TIM_PWM_ConfigChannel(&htim8, &sConfigOC, TIM_CHANNEL_3) != HAL_OK)
  {
    Error_Handler();
  }
  sBreakDeadTimeConfig.OffStateRunMode = TIM_OSSR_ENABLE;
  sBreakDeadTimeConfig.OffStateIDLEMode = TIM_OSSI_ENABLE;
  sBreakDeadTimeConfig.LockLevel = TIM_LOCKLEVEL_OFF;
  sBreakDeadTimeConfig.DeadTime = 0;
  sBreakDeadTimeConfig.BreakState = TIM_BREAK_ENABLE;
  sBreakDeadTimeConfig.BreakPolarity = TIM_BREAKPOLARITY_HIGH;
  sBreakDeadTimeConfig.BreakFilter = 0;
  sBreakDeadTimeConfig.BreakAFMode = TIM_BREAK_AFMODE_INPUT;
  sBreakDeadTimeConfig.Break2State = TIM_BREAK2_ENABLE;
  sBreakDeadTimeConfig.Break2Polarity = TIM_BREAK2POLARITY_HIGH;
  sBreakDeadTimeConfig.Break2Filter = 0;
  sBreakDeadTimeConfig.Break2AFMode = TIM_BREAK_AFMODE_INPUT;
  sBreakDeadTimeConfig.AutomaticOutput = TIM_AUTOMATICOUTPUT_DISABLE;
  if (HAL_TIMEx_ConfigBreakDeadTime(&htim8, &sBreakDeadTimeConfig) != HAL_OK)
  {
    Error_Handler();
  }
  HAL_TIM_MspPostInit(&htim8);

}

static void MX_TIM15_Init(void)
{

  TIM_SlaveConfigTypeDef sSlaveConfig = {0};
  TIM_MasterConfigTypeDef sMasterConfig = {0};

  htim15.Instance = TIM15;
  htim15.Init.Prescaler = 0;
  htim15.Init.CounterMode = TIM_COUNTERMODE_UP;
  htim15.Init.Period = 65535;
  htim15.Init.ClockDivision = TIM_CLOCKDIVISION_DIV1;
  htim15.Init.RepetitionCounter = 0;
  htim15.Init.AutoReloadPreload = TIM_AUTORELOAD_PRELOAD_DISABLE;
  if (HAL_TIM_Base_Init(&htim15) != HAL_OK)
  {
    Error_Handler();
  }
  sSlaveConfig.SlaveMode = TIM_SLAVEMODE_EXTERNAL1;
  sSlaveConfig.InputTrigger = TIM_TS_TI1FP1;
  sSlaveConfig.TriggerPolarity = TIM_TRIGGERPOLARITY_RISING;
  sSlaveConfig.TriggerFilter = 15;
  if (HAL_TIM_SlaveConfigSynchro(&htim15, &sSlaveConfig) != HAL_OK)
  {
    Error_Handler();
  }
  sMasterConfig.MasterOutputTrigger = TIM_TRGO_RESET;
  sMasterConfig.MasterSlaveMode = TIM_MASTERSLAVEMODE_DISABLE;
  if (HAL_TIMEx_MasterConfigSynchronization(&htim15, &sMasterConfig) != HAL_OK)
  {
    Error_Handler();
  }

}

static void MX_TIM17_Init(void)
{

  TIM_OC_InitTypeDef sConfigOC = {0};
  TIM_BreakDeadTimeConfigTypeDef sBreakDeadTimeConfig = {0};

  htim17.Instance = TIM17;
  htim17.Init.Prescaler = 3;
  htim17.Init.CounterMode = TIM_COUNTERMODE_UP;
  htim17.Init.Period = 1000;
  htim17.Init.ClockDivision = TIM_CLOCKDIVISION_DIV1;
  htim17.Init.RepetitionCounter = 0;
  htim17.Init.AutoReloadPreload = TIM_AUTORELOAD_PRELOAD_ENABLE;
  if (HAL_TIM_Base_Init(&htim17) != HAL_OK)
  {
    Error_Handler();
  }
  if (HAL_TIM_PWM_Init(&htim17) != HAL_OK)
  {
    Error_Handler();
  }
  sConfigOC.OCMode = TIM_OCMODE_PWM1;
  sConfigOC.Pulse = 500;
  sConfigOC.OCPolarity = TIM_OCPOLARITY_HIGH;
  sConfigOC.OCNPolarity = TIM_OCNPOLARITY_HIGH;
  sConfigOC.OCFastMode = TIM_OCFAST_DISABLE;
  sConfigOC.OCIdleState = TIM_OCIDLESTATE_RESET;
  sConfigOC.OCNIdleState = TIM_OCNIDLESTATE_RESET;
  if (HAL_TIM_PWM_ConfigChannel(&htim17, &sConfigOC, TIM_CHANNEL_1) != HAL_OK)
  {
    Error_Handler();
  }
  sBreakDeadTimeConfig.OffStateRunMode = TIM_OSSR_DISABLE;
  sBreakDeadTimeConfig.OffStateIDLEMode = TIM_OSSI_DISABLE;
  sBreakDeadTimeConfig.LockLevel = TIM_LOCKLEVEL_OFF;
  sBreakDeadTimeConfig.DeadTime = 0;
  sBreakDeadTimeConfig.BreakState = TIM_BREAK_DISABLE;
  sBreakDeadTimeConfig.BreakPolarity = TIM_BREAKPOLARITY_HIGH;
  sBreakDeadTimeConfig.BreakFilter = 0;
  sBreakDeadTimeConfig.AutomaticOutput = TIM_AUTOMATICOUTPUT_DISABLE;
  if (HAL_TIMEx_ConfigBreakDeadTime(&htim17, &sBreakDeadTimeConfig) != HAL_OK)
  {
    Error_Handler();
  }
  HAL_TIM_MspPostInit(&htim17);

}

static void MX_TIM20_Init(void)
{

  TIM_ClockConfigTypeDef sClockSourceConfig = {0};
  TIM_MasterConfigTypeDef sMasterConfig = {0};
  TIMEx_BreakInputConfigTypeDef sBreakInputConfig = {0};
  TIM_OC_InitTypeDef sConfigOC = {0};
  TIM_BreakDeadTimeConfigTypeDef sBreakDeadTimeConfig = {0};

  htim20.Instance = TIM20;
  htim20.Init.Prescaler = 0;
  htim20.Init.CounterMode = TIM_COUNTERMODE_UP;
  htim20.Init.Period = 65535;
  htim20.Init.ClockDivision = TIM_CLOCKDIVISION_DIV1;
  htim20.Init.RepetitionCounter = 0;
  htim20.Init.AutoReloadPreload = TIM_AUTORELOAD_PRELOAD_DISABLE;
  if (HAL_TIM_Base_Init(&htim20) != HAL_OK)
  {
    Error_Handler();
  }
  sClockSourceConfig.ClockSource = TIM_CLOCKSOURCE_INTERNAL;
  if (HAL_TIM_ConfigClockSource(&htim20, &sClockSourceConfig) != HAL_OK)
  {
    Error_Handler();
  }
  if (HAL_TIM_PWM_Init(&htim20) != HAL_OK)
  {
    Error_Handler();
  }
  sMasterConfig.MasterOutputTrigger = TIM_TRGO_RESET;
  sMasterConfig.MasterOutputTrigger2 = TIM_TRGO2_RESET;
  sMasterConfig.MasterSlaveMode = TIM_MASTERSLAVEMODE_DISABLE;
  if (HAL_TIMEx_MasterConfigSynchronization(&htim20, &sMasterConfig) != HAL_OK)
  {
    Error_Handler();
  }
  sBreakInputConfig.Source = TIM_BREAKINPUTSOURCE_BKIN;
  sBreakInputConfig.Enable = TIM_BREAKINPUTSOURCE_ENABLE;
  sBreakInputConfig.Polarity = TIM_BREAKINPUTSOURCE_POLARITY_HIGH;
  if (HAL_TIMEx_ConfigBreakInput(&htim20, TIM_BREAKINPUT_BRK, &sBreakInputConfig) != HAL_OK)
  {
    Error_Handler();
  }
  if (HAL_TIMEx_ConfigBreakInput(&htim20, TIM_BREAKINPUT_BRK2, &sBreakInputConfig) != HAL_OK)
  {
    Error_Handler();
  }
  sConfigOC.OCMode = TIM_OCMODE_PWM1;
  sConfigOC.Pulse = 0;
  sConfigOC.OCPolarity = TIM_OCPOLARITY_HIGH;
  sConfigOC.OCNPolarity = TIM_OCNPOLARITY_HIGH;
  sConfigOC.OCFastMode = TIM_OCFAST_DISABLE;
  sConfigOC.OCIdleState = TIM_OCIDLESTATE_RESET;
  sConfigOC.OCNIdleState = TIM_OCNIDLESTATE_RESET;
  if (HAL_TIM_PWM_ConfigChannel(&htim20, &sConfigOC, TIM_CHANNEL_1) != HAL_OK)
  {
    Error_Handler();
  }
  if (HAL_TIM_PWM_ConfigChannel(&htim20, &sConfigOC, TIM_CHANNEL_2) != HAL_OK)
  {
    Error_Handler();
  }
  if (HAL_TIM_PWM_ConfigChannel(&htim20, &sConfigOC, TIM_CHANNEL_3) != HAL_OK)
  {
    Error_Handler();
  }
  sBreakDeadTimeConfig.OffStateRunMode = TIM_OSSR_ENABLE;
  sBreakDeadTimeConfig.OffStateIDLEMode = TIM_OSSI_ENABLE;
  sBreakDeadTimeConfig.LockLevel = TIM_LOCKLEVEL_OFF;
  sBreakDeadTimeConfig.DeadTime = 0;
  sBreakDeadTimeConfig.BreakState = TIM_BREAK_ENABLE;
  sBreakDeadTimeConfig.BreakPolarity = TIM_BREAKPOLARITY_HIGH;
  sBreakDeadTimeConfig.BreakFilter = 0;
  sBreakDeadTimeConfig.BreakAFMode = TIM_BREAK_AFMODE_INPUT;
  sBreakDeadTimeConfig.Break2State = TIM_BREAK2_ENABLE;
  sBreakDeadTimeConfig.Break2Polarity = TIM_BREAK2POLARITY_HIGH;
  sBreakDeadTimeConfig.Break2Filter = 0;
  sBreakDeadTimeConfig.Break2AFMode = TIM_BREAK_AFMODE_INPUT;
  sBreakDeadTimeConfig.AutomaticOutput = TIM_AUTOMATICOUTPUT_DISABLE;
  if (HAL_TIMEx_ConfigBreakDeadTime(&htim20, &sBreakDeadTimeConfig) != HAL_OK)
  {
    Error_Handler();
  }
  HAL_TIM_MspPostInit(&htim20);

}

static void MX_USART1_UART_Init(void)
{

  huart1.Instance = USART1;
  huart1.Init.BaudRate = 12500000;
  huart1.Init.WordLength = UART_WORDLENGTH_8B;
  huart1.Init.StopBits = UART_STOPBITS_1;
  huart1.Init.Parity = UART_PARITY_NONE;
  huart1.Init.Mode = UART_MODE_TX_RX;
  huart1.Init.HwFlowCtl = UART_HWCONTROL_NONE;
  huart1.Init.OverSampling = UART_OVERSAMPLING_8;
  huart1.Init.OneBitSampling = UART_ONE_BIT_SAMPLE_DISABLE;
  huart1.Init.ClockPrescaler = UART_PRESCALER_DIV1;
  huart1.AdvancedInit.AdvFeatureInit = UART_ADVFEATURE_NO_INIT;
  if (HAL_UART_Init(&huart1) != HAL_OK)
  {
    Error_Handler();
  }
  if (HAL_UARTEx_SetTxFifoThreshold(&huart1, UART_TXFIFO_THRESHOLD_1_8) != HAL_OK)
  {
    Error_Handler();
  }
  if (HAL_UARTEx_SetRxFifoThreshold(&huart1, UART_RXFIFO_THRESHOLD_1_8) != HAL_OK)
  {
    Error_Handler();
  }
  if (HAL_UARTEx_DisableFifoMode(&huart1) != HAL_OK)
  {
    Error_Handler();
  }

}

static void MX_USART2_UART_Init(void)
{

  huart2.Instance = USART2;
  huart2.Init.BaudRate = 115200;
  huart2.Init.WordLength = UART_WORDLENGTH_8B;
  huart2.Init.StopBits = UART_STOPBITS_1;
  huart2.Init.Parity = UART_PARITY_NONE;
  huart2.Init.Mode = UART_MODE_TX_RX;
  huart2.Init.HwFlowCtl = UART_HWCONTROL_NONE;
  huart2.Init.OverSampling = UART_OVERSAMPLING_16;
  huart2.Init.OneBitSampling = UART_ONE_BIT_SAMPLE_DISABLE;
  huart2.Init.ClockPrescaler = UART_PRESCALER_DIV1;
  huart2.AdvancedInit.AdvFeatureInit = UART_ADVFEATURE_NO_INIT;
  if (HAL_UART_Init(&huart2) != HAL_OK)
  {
    Error_Handler();
  }
  if (HAL_UARTEx_SetTxFifoThreshold(&huart2, UART_TXFIFO_THRESHOLD_1_8) != HAL_OK)
  {
    Error_Handler();
  }
  if (HAL_UARTEx_SetRxFifoThreshold(&huart2, UART_RXFIFO_THRESHOLD_1_8) != HAL_OK)
  {
    Error_Handler();
  }
  if (HAL_UARTEx_DisableFifoMode(&huart2) != HAL_OK)
  {
    Error_Handler();
  }

}

static void MX_USART3_UART_Init(void)
{

  huart3.Instance = USART3;
  huart3.Init.BaudRate = 115200;
  huart3.Init.WordLength = UART_WORDLENGTH_8B;
  huart3.Init.StopBits = UART_STOPBITS_1;
  huart3.Init.Parity = UART_PARITY_NONE;
  huart3.Init.Mode = UART_MODE_TX_RX;
  huart3.Init.HwFlowCtl = UART_HWCONTROL_NONE;
  huart3.Init.OverSampling = UART_OVERSAMPLING_16;
  huart3.Init.OneBitSampling = UART_ONE_BIT_SAMPLE_DISABLE;
  huart3.Init.ClockPrescaler = UART_PRESCALER_DIV1;
  huart3.AdvancedInit.AdvFeatureInit = UART_ADVFEATURE_NO_INIT;
  if (HAL_UART_Init(&huart3) != HAL_OK)
  {
    Error_Handler();
  }
  if (HAL_UARTEx_SetTxFifoThreshold(&huart3, UART_TXFIFO_THRESHOLD_1_8) != HAL_OK)
  {
    Error_Handler();
  }
  if (HAL_UARTEx_SetRxFifoThreshold(&huart3, UART_RXFIFO_THRESHOLD_1_8) != HAL_OK)
  {
    Error_Handler();
  }
  if (HAL_UARTEx_DisableFifoMode(&huart3) != HAL_OK)
  {
    Error_Handler();
  }

}

static void MX_GPIO_Init(void)
{
  GPIO_InitTypeDef GPIO_InitStruct = {0};

  /* GPIO Ports Clock Enable */
  __HAL_RCC_GPIOE_CLK_ENABLE();
  __HAL_RCC_GPIOC_CLK_ENABLE();
  __HAL_RCC_GPIOF_CLK_ENABLE();
  __HAL_RCC_GPIOA_CLK_ENABLE();
  __HAL_RCC_GPIOB_CLK_ENABLE();
  __HAL_RCC_GPIOD_CLK_ENABLE();
  __HAL_RCC_GPIOG_CLK_ENABLE();

  /*Configure GPIO pin Output Level */
  HAL_GPIO_WritePin(GPIOE, GPIO_PIN_4|GPIO_PIN_5|GPIO_PIN_6, GPIO_PIN_RESET);

  /*Configure GPIO pin Output Level */
  HAL_GPIO_WritePin(GPIOC, GPIO_PIN_13, GPIO_PIN_RESET);

  /*Configure GPIO pin Output Level */
  HAL_GPIO_WritePin(GPIOA, GPIO_PIN_11|GPIO_PIN_12, GPIO_PIN_RESET);

  /*Configure GPIO pin Output Level */
  HAL_GPIO_WritePin(GPIOF, GPIO_PIN_6, GPIO_PIN_RESET);

  /*Configure GPIO pin Output Level */
  HAL_GPIO_WritePin(GPIOG, GPIO_PIN_5|GPIO_PIN_6, GPIO_PIN_RESET);

  /*Configure GPIO pin Output Level */
  HAL_GPIO_WritePin(GPIOD, GPIO_PIN_4, GPIO_PIN_RESET);

  /*Configure GPIO pins : PE4 PE5 PE6 */
  GPIO_InitStruct.Pin = GPIO_PIN_4|GPIO_PIN_5|GPIO_PIN_6;
  GPIO_InitStruct.Mode = GPIO_MODE_OUTPUT_PP;
  GPIO_InitStruct.Pull = GPIO_NOPULL;
  GPIO_InitStruct.Speed = GPIO_SPEED_FREQ_LOW;
  HAL_GPIO_Init(GPIOE, &GPIO_InitStruct);

  /*Configure GPIO pin : PC13 */
  GPIO_InitStruct.Pin = GPIO_PIN_13;
  GPIO_InitStruct.Mode = GPIO_MODE_OUTPUT_PP;
  GPIO_InitStruct.Pull = GPIO_NOPULL;
  GPIO_InitStruct.Speed = GPIO_SPEED_FREQ_LOW;
  HAL_GPIO_Init(GPIOC, &GPIO_InitStruct);

  /*Configure GPIO pin : PB0 */
  GPIO_InitStruct.Pin = GPIO_PIN_0;
  GPIO_InitStruct.Mode = GPIO_MODE_ANALOG;
  GPIO_InitStruct.Pull = GPIO_NOPULL;
  HAL_GPIO_Init(GPIOB, &GPIO_InitStruct);

  /*Configure GPIO pins : PF11 PF12 PF13 */
  GPIO_InitStruct.Pin = GPIO_PIN_11|GPIO_PIN_12|GPIO_PIN_13;
  GPIO_InitStruct.Mode = GPIO_MODE_INPUT;
  GPIO_InitStruct.Pull = GPIO_NOPULL;
  HAL_GPIO_Init(GPIOF, &GPIO_InitStruct);

  /*Configure GPIO pins : PA11 PA12 */
  GPIO_InitStruct.Pin = GPIO_PIN_11|GPIO_PIN_12;
  GPIO_InitStruct.Mode = GPIO_MODE_OUTPUT_PP;
  GPIO_InitStruct.Pull = GPIO_NOPULL;
  GPIO_InitStruct.Speed = GPIO_SPEED_FREQ_LOW;
  HAL_GPIO_Init(GPIOA, &GPIO_InitStruct);

  /*Configure GPIO pin : PF6 */
  GPIO_InitStruct.Pin = GPIO_PIN_6;
  GPIO_InitStruct.Mode = GPIO_MODE_OUTPUT_PP;
  GPIO_InitStruct.Pull = GPIO_NOPULL;
  GPIO_InitStruct.Speed = GPIO_SPEED_FREQ_LOW;
  HAL_GPIO_Init(GPIOF, &GPIO_InitStruct);

  /*Configure GPIO pins : PG5 PG6 */
  GPIO_InitStruct.Pin = GPIO_PIN_5|GPIO_PIN_6;
  GPIO_InitStruct.Mode = GPIO_MODE_OUTPUT_PP;
  GPIO_InitStruct.Pull = GPIO_NOPULL;
  GPIO_InitStruct.Speed = GPIO_SPEED_FREQ_LOW;
  HAL_GPIO_Init(GPIOG, &GPIO_InitStruct);

  /*Configure GPIO pin : PD4 */
  GPIO_InitStruct.Pin = GPIO_PIN_4;
  GPIO_InitStruct.Mode = GPIO_MODE_OUTPUT_PP;
  GPIO_InitStruct.Pull = GPIO_NOPULL;
  GPIO_InitStruct.Speed = GPIO_SPEED_FREQ_LOW;
  HAL_GPIO_Init(GPIOD, &GPIO_InitStruct);

  /*Configure GPIO pin : PE0 */
  GPIO_InitStruct.Pin = GPIO_PIN_0;
  GPIO_InitStruct.Mode = GPIO_MODE_AF_PP;
  GPIO_InitStruct.Pull = GPIO_NOPULL;
  GPIO_InitStruct.Speed = GPIO_SPEED_FREQ_LOW;
  GPIO_InitStruct.Alternate = GPIO_AF2_TIM4;
  HAL_GPIO_Init(GPIOE, &GPIO_InitStruct);

}

void Error_Handler(void)
{
  __disable_irq();
  while (1)
  {
  }
}
